# CY8C5868AXI_LP035 register map
File version: 0.1
CY8C58LP
Registers are 8-bit, read-write, no defined reset value unless marked. A register's access mark holds for its fields unless they carry their own. Offsets are from the block's base; lines under a group give offsets from that group; [hi:lo] are bit positions; {n}, {i} and the like mark numbered series; 'fields as' and 'values as' point back to an identical list; <NAME> marks a mode.

## Memory map
0x400043AA ADC size 0x17E0
0x40006408 Timer size 0x93
0x4000642C PWM size 0x72
0x4000650A Counter size 0x92

## Timer
Base 0x40006408
0x00 Timer_COUNTER 24-bit — UDB.A0 - Current Down Counter Value
0x20 Timer_PERIOD 24-bit — UDB.D0 - Assigned Period
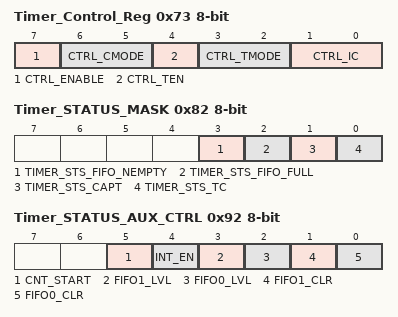
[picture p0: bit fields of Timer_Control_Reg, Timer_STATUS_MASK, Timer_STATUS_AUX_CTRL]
0x73 Timer_Control_Reg — UDB Control Register - Assigned Control Register Value
  [7] CTRL_ENABLE — Enable the Timer
  [6:5] CTRL_CMODE — Capture Mode
  [4] CTRL_TEN — Trigger Enable Bit
  [3:2] CTRL_TMODE — Trigger Mode
  [1:0] CTRL_IC — Interrupt Count
0x82 Timer_STATUS_MASK — UDB Status bits Interrupt Mask Enable Register
  [3] TIMER_STS_FIFO_NEMPTY ro — FIFO Empty status
  [2] TIMER_STS_FIFO_FULL ro — FIFO Full Status
  [1] TIMER_STS_CAPT ro — Enables the Interrupt on Capture
  [0] TIMER_STS_TC ro — Enables the Interrupt on TC
0x92 Timer_STATUS_AUX_CTRL — UDB Auxilliary Control Register
  [5] CNT_START — FIFO0 clear
    0=E_CNT_START0 (Disable counter); 1=E_CNT_START1 (Enable counter)
  [4] INT_EN
    0=E_INT_EN0 (Interrupt disabled); 1=E_INT_EN1 (Interrupt enabled)
  [3] FIFO1_LVL — FIFO level
    0=E_FIFO_LVL_0 (FIFO LVL: input mode: FIFO not full; output mode: FIFO not empty); 1=E_FIFO_LVL_1 (FIFO LVL: input mode: FIFO at least 1/2 empty; output mode: FIFO at least 1/2 full)
  [2] FIFO0_LVL — FIFO level
    values as FIFO1_LVL
  [1] FIFO1_CLR — FIFO1 clear
    0=E_FIFO_CLR_0 (Normal FIFO operation); 1=E_FIFO_CLR_1 (Clear FIFO state)
  [0] FIFO0_CLR — FIFO0 clear
    values as FIFO1_CLR

## Counter
Base 0x4000650A
0x00 Counter_COUNTER 16-bit — UDB.A0 - Current Counter Value
0x20 Counter_PERIOD 16-bit — UDB.D0 - Assigned Period
0x30 Counter_COMPARE 16-bit — UDB.D1 - Assigned Compare Value
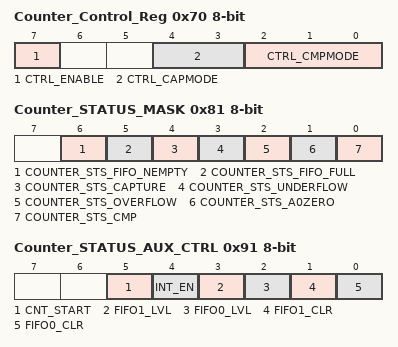
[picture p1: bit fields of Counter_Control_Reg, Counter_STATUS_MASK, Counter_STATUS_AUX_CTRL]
0x70 Counter_Control_Reg — UDB Control Register - Assigned Control Register Value
  [7] CTRL_ENABLE — Enable Counter
  [4:3] CTRL_CAPMODE — Capture mode
  [2:0] CTRL_CMPMODE — Compare mode
0x81 Counter_STATUS_MASK — UDB Status bits Interrupt Mask Enable Register
  [6] COUNTER_STS_FIFO_NEMPTY — FIFO Not Empty Status
  [5] COUNTER_STS_FIFO_FULL — FIFO Full Status
  [4] COUNTER_STS_CAPTURE — Capture Status
  [3] COUNTER_STS_UNDERFLOW — Underflow status
  [2] COUNTER_STS_OVERFLOW — Overflow status
  [1] COUNTER_STS_A0ZERO — A0 Zero ouput status
  [0] COUNTER_STS_CMP — Compare output status
0x91 Counter_STATUS_AUX_CTRL — UDB Auxilliary Control Register
  [5] CNT_START — FIFO0 clear
    0=E_CNT_START0 (Disable counter); 1=E_CNT_START1 (Enable counter)
  [4] INT_EN
    0=E_INT_EN0 (Interrupt disabled); 1=E_INT_EN1 (Interrupt enabled)
  [3] FIFO1_LVL — FIFO level
    0=E_FIFO_LVL_0 (FIFO LVL: input mode: FIFO not full; output mode: FIFO not empty); 1=E_FIFO_LVL_1 (FIFO LVL: input mode: FIFO at least 1/2 empty; output mode: FIFO at least 1/2 full)
  [2] FIFO0_LVL — FIFO level
    values as FIFO1_LVL
  [1] FIFO1_CLR — FIFO1 clear
    0=E_FIFO_CLR_0 (Normal FIFO operation); 1=E_FIFO_CLR_1 (Clear FIFO state)
  [0] FIFO0_CLR — FIFO0 clear
    values as FIFO1_CLR

## PWM
Base 0x4000642C
0x00 PWM_COMPARE_Reg 16-bit — UDB.D0 - Assigned Compare Value
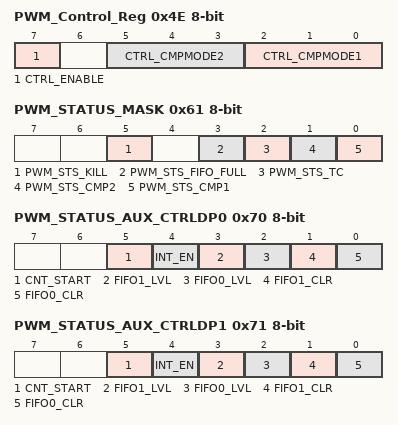
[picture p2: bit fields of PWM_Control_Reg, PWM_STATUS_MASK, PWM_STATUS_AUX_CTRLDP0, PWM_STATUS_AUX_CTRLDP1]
0x4E PWM_Control_Reg — UDB Control Register - Assigned Control Register Value
  [7] CTRL_ENABLE — Enable the PWM
  [5:3] CTRL_CMPMODE2 — Compare mode 2
  [2:0] CTRL_CMPMODE1 — Compare mode 1
0x61 PWM_STATUS_MASK — UDB Status bits Interrupt Mask Enable Register
  [5] PWM_STS_KILL ro — Enables the Interrupt on Kill
  [3] PWM_STS_FIFO_FULL ro — FIFO Full Status Mask
  [2] PWM_STS_TC ro — Enables the Interrupt on Terminal Count
  [1] PWM_STS_CMP2 ro — Enables the Interrupt on Compare 2
  [0] PWM_STS_CMP1 ro — Enables the Interrupt on Compare 1
0x70 PWM_STATUS_AUX_CTRLDP0 — UDB Auxilliary Control Register
  [5] CNT_START — FIFO0 clear
    0=E_CNT_START0 (Disable counter); 1=E_CNT_START1 (Enable counter)
  [4] INT_EN
    0=E_INT_EN0 (Interrupt disabled); 1=E_INT_EN1 (Interrupt enabled)
  [3] FIFO1_LVL — FIFO level
    0=E_FIFO_LVL_0 (FIFO LVL: input mode: FIFO not full; output mode: FIFO not empty); 1=E_FIFO_LVL_1 (FIFO LVL: input mode: FIFO at least 1/2 empty; output mode: FIFO at least 1/2 full)
  [2] FIFO0_LVL — FIFO level
    values as FIFO1_LVL
  [1] FIFO1_CLR — FIFO1 clear
    0=E_FIFO_CLR_0 (Normal FIFO operation); 1=E_FIFO_CLR_1 (Clear FIFO state)
  [0] FIFO0_CLR — FIFO0 clear
    values as FIFO1_CLR
0x71 PWM_STATUS_AUX_CTRLDP1 — UDB Auxilliary Control Register
  fields as PWM_STATUS_AUX_CTRLDP0
